# cslr_gpio_002 register map
Vendor: Texas Instruments
Peripheral module from a debugger description file.
Registers are 32-bit, read-write, reset 0x0 unless marked. A register's access mark holds for its fields unless they carry their own. Offsets are as the file gives them; lines under a group give offsets from that group; [hi:lo] are bit positions; {n}, {i} and the like mark numbered series; 'fields as' and 'values as' point back to an identical list; <NAME> marks a mode.

## GPIO — General Purpose Input Output
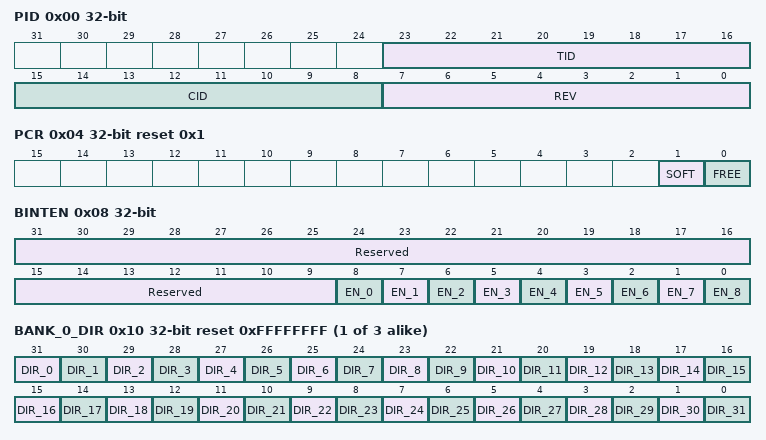
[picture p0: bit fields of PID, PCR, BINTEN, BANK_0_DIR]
0x00 PID ro — Peripheral ID Register
  [23:16] TID — Peripheral type ID
  [15:8] CID — Peripheral class ID
  [7:0] REV — Peripheral revision number
0x04 PCR ro reset 0x1 — Peripheral Control Register
  [1] SOFT — Used along with FREE bit to determine the emulation suspend mode. Conventionally, when FREE bit is cleared, SOFT bit selects the mode. GPIO has FREE = 1, so SOFT bit does not affect functionality
  [0] FREE — For GPIO, the FREE bit is fixed at 1, which means GPIO runs free in emulation suspend mode
0x08 BINTEN access not given (reset mask 0x1FF) — GPIO Interrupt Per-Bank Enable Register
  [31:9] Reserved — (access N)
  [8-n] EN_{n} rw (n=0..8) — Per-bank interrupt enable There are 9 banks of 16 GPIOs each. Bit i stands for bank i
    0=DISABLE; 1=ENABLE
0x10 BANK_{i}_DIR reset 0xFFFFFFFF (i=0..2) — GPIO Direction i and i+1 Register
  [all] fields
    0=OUT (Output); 1=IN (Input)
  [31-n] DIR_{n} (n=0..31) — Direction of GPIO bank 2i/2i+1 bit 0...15 Bits 0-15 form bank 2i and bits 16-31 form bank 2i+1
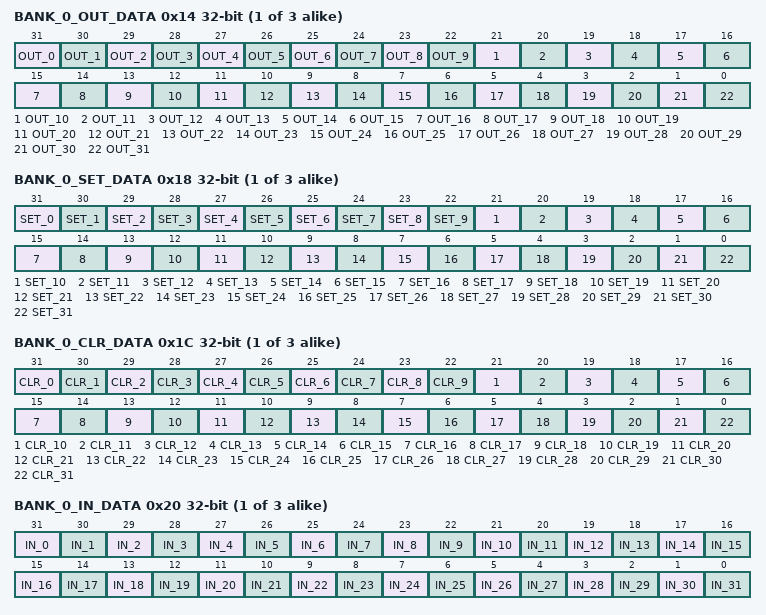
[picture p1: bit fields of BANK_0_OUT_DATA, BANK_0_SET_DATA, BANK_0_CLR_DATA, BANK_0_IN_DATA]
0x14 BANK_{i}_OUT_DATA (i=0..2) — GPIO Output Data 2i and 2i+1 Register
  [31-n] OUT_{n} (n=0..31) — Output drive state of GPIO bank 2i/2i+1 bit 0...15 Bits 0-15 form bank 2i and bits 16-31 form bank 2i+1 (Ignored when configured as Input)
0x18 BANK_{i}_SET_DATA (i=0..2) — GPIO Set Data 2i and 2i+1 Register
  [all] fields
    1=SET (Set output to 1)
  [31-n] SET_{n} (n=0..31) — Set output drive state of GPIO bank 2i/2i+1 bit 0...15 Bits 0-15 form bank 2i and bits 16-31 form bank 2i+1 Writing 1 sets the output drive state of corresponding GPIO. Reading it returns the output drive state
0x1C BANK_{i}_CLR_DATA (i=0..2) — GPIO Clear Data 2i and 2i+1 Register
  [all] fields
    1=CLR (Clear output to 0)
  [31-n] CLR_{n} (n=0..31) — Clear output drive state of GPIO bank 2i/2i+1 bit 0...15 Bits 0-15 form bank 2i and bits 16-31 form bank 2i+1 Writing 1 clears the output drive state of corresponding GPIO. Reading it returns the output drive state
0x20 BANK_{i}_IN_DATA ro (i=0..2) — GPIO Input Data 2i and 2i+1 Register
  [all] fields
    1=SET; 0=CLR
  [31-n] IN_{n} (n=0..31) — Status of GPIO bank 2i/2i+1 bit 0...15 Bits 0-15 form bank 2i and bits 16-31 form bank 2i+1
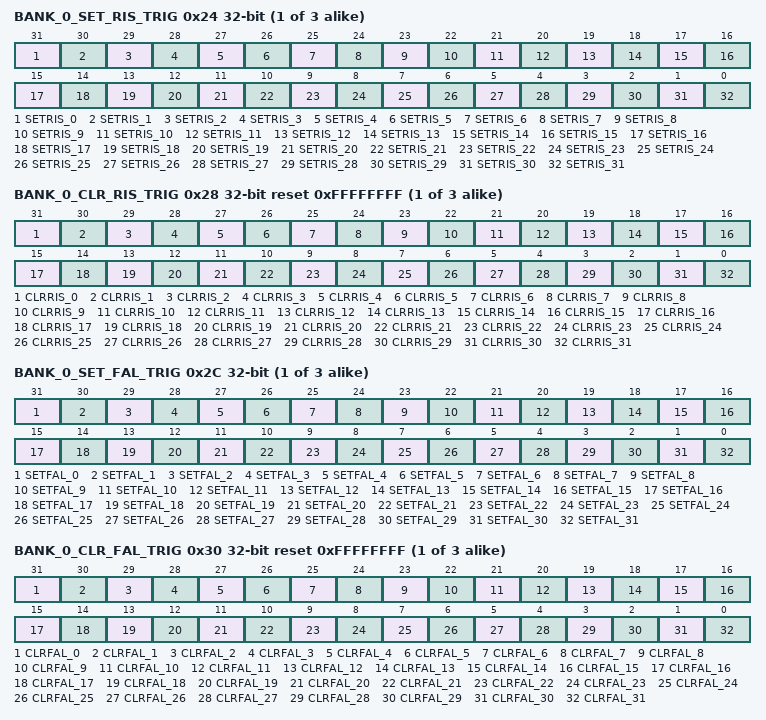
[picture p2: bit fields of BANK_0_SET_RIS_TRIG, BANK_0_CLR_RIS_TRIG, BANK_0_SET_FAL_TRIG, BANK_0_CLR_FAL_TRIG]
0x24 BANK_{i}_SET_RIS_TRIG (i=0..2) — GPIO Set Rising Edge Interrupt 2i and 2i+1 Register
  [all] fields
    1=ENABLE
  [31-n] SETRIS_{n} (n=0..31) — Enable Rising edge interrupt detection for GPIO bank 2i/2i+1 bit 0...15 Bits 0-15 form bank 2i and bits 16-31 form bank 2i+1 Reading returns state of RIS_TRG
0x28 BANK_{i}_CLR_RIS_TRIG reset 0xFFFFFFFF (i=0..2) — GPIO Clear Rising Edge Interrupt 2i and 2i+1 Register
  [all] fields
    0=DISABLE
  [31-n] CLRRIS_{n} (n=0..31) — Disable Rising edge interrupt detection for GPIO bank 2i/2i+1 bit 0...15 Bits 0-15 form bank 2i and bits 16-31 form bank 2i+1 Reading returns complement state of RIS_TRG
0x2C BANK_{i}_SET_FAL_TRIG (i=0..2) — GPIO Set Falling Edge Interrupt 2i and 2i+1 Register
  [all] fields
    1=ENABLE
  [31-n] SETFAL_{n} (n=0..31) — Enable Falling edge interrupt detection for GPIO bank 2i/2i+1 bit 0...15 Bits 0-15 form bank 2i and bits 16-31 form bank 2i+1 Reading returns state of FAL_TRG
0x30 BANK_{i}_CLR_FAL_TRIG reset 0xFFFFFFFF (i=0..2) — GPIO Clear Falling Edge Interrupt 2i and 2i+1 Register
  [all] fields
    0=DISABLE
  [31-n] CLRFAL_{n} (n=0..31) — Disable Falling edge interrupt detection for GPIO bank 2i/2i+1 bit 0...15 Bits 0-15 form bank 2i and bits 16-31 form bank 2i+1 Reading returns complement state of FAL_TRG
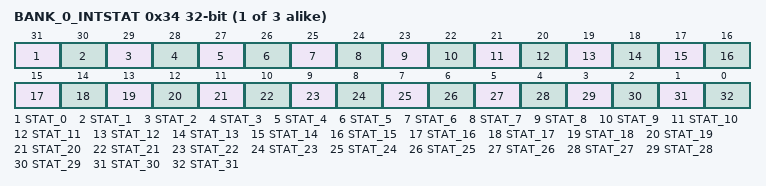
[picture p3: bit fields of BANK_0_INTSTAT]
0x34 BANK_{i}_INTSTAT (i=0..2) — GPIO Interrupt Status 2i and 2i+1 Register
  [31-n] STAT_{n} (n=0..31) — Status of GPIO bank 2i/2i+1 bit 0...15 interrupt Bits 0-15 form bank 2i and bits 16-31 form bank 2i+1 Reading 0: Interrupt didn't occur Reading 1: Interrupt occurred Writing 1: Clear interrupt status
